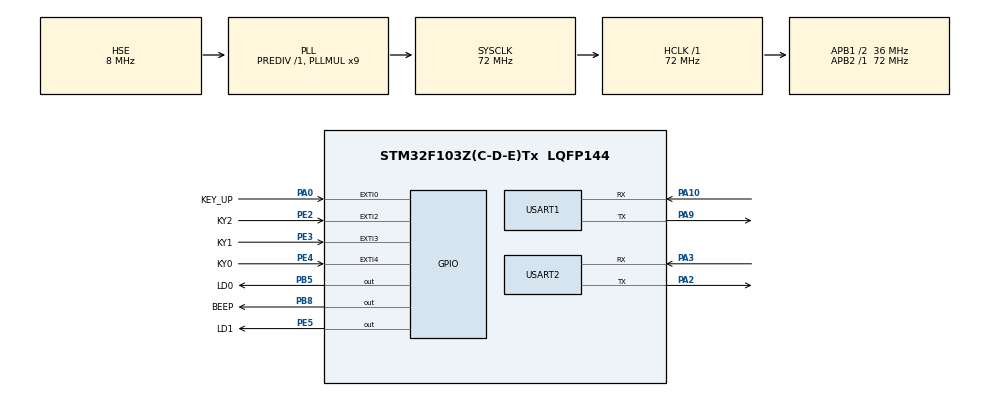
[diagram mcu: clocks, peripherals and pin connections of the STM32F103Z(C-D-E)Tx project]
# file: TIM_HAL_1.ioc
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Mcu.Family=STM32F1
Mcu.Name=STM32F103Z(C-D-E)Tx
Mcu.Package=LQFP144
NVIC.EXTI0_IRQn=true\:2\:0\:true\:false\:true\:true\:true
NVIC.EXTI2_IRQn=true\:3\:0\:true\:false\:true\:true\:true
NVIC.EXTI3_IRQn=true\:4\:0\:true\:false\:true\:true\:true
NVIC.EXTI4_IRQn=true\:5\:0\:true\:false\:true\:true\:true
NVIC.PriorityGroup=NVIC_PRIORITYGROUP_4
NVIC.TIM1_UP_IRQn=true\:0\:0\:false\:false\:true\:true\:true
NVIC.TIM4_IRQn=true\:0\:0\:false\:false\:true\:true\:true
NVIC.USART1_IRQn=true\:0\:0\:false\:false\:true\:true\:true
NVIC.USART2_IRQn=true\:0\:0\:false\:false\:true\:true\:true
OSC_IN.Mode=HSE-External-Oscillator
OSC_IN.Signal=RCC_OSC_IN
OSC_OUT.Mode=HSE-External-Oscillator
OSC_OUT.Signal=RCC_OSC_OUT
PA0-WKUP.GPIO_Label=KEY_UP
PA0-WKUP.GPIO_PuPd=GPIO_PULLDOWN
PA0-WKUP.Signal=GPXTI0
PA10.Mode=Asynchronous
PA10.Signal=USART1_RX
PA13.Mode=Serial_Wire
PA13.Signal=SYS_JTMS-SWDIO
PA14.Mode=Serial_Wire
PA14.Signal=SYS_JTCK-SWCLK
PA2.Mode=Asynchronous
PA2.Signal=USART2_TX
PA3.Mode=Asynchronous
PA3.Signal=USART2_RX
PA9.Mode=Asynchronous
PA9.Signal=USART1_TX
PB5.GPIO_Label=LD0
PB5.GPIO_PuPd=GPIO_PULLUP
PB5.Signal=GPIO_Output
PB8.GPIO_Label=BEEP
PB8.GPIO_PuPd=GPIO_PULLUP
PB8.Signal=GPIO_Output
PC14-OSC32_IN.Mode=LSE-External-Oscillator
PC14-OSC32_IN.Signal=RCC_OSC32_IN
PC15-OSC32_OUT.Mode=LSE-External-Oscillator
PC15-OSC32_OUT.Signal=RCC_OSC32_OUT
PE2.GPIO_Label=KY2
PE2.GPIO_ModeDefaultEXTI=GPIO_MODE_IT_FALLING
PE2.GPIO_PuPd=GPIO_PULLUP
PE2.Signal=GPXTI2
PE3.GPIO_Label=KY1
PE3.GPIO_ModeDefaultEXTI=GPIO_MODE_IT_FALLING
PE3.GPIO_PuPd=GPIO_PULLUP
PE3.Signal=GPXTI3
PE4.GPIO_Label=KY0
PE4.GPIO_ModeDefaultEXTI=GPIO_MODE_IT_FALLING
PE4.GPIO_PuPd=GPIO_PULLUP
PE4.Signal=GPXTI4
PE5.GPIO_Label=LD1
PE5.GPIO_PuPd=GPIO_PULLUP
PE5.Signal=GPIO_Output
ProjectManager.HeapSize=0x200
ProjectManager.StackSize=0x400
ProjectManager.TargetToolchain=MDK-ARM V5
RCC.AHBFreq_Value=72000000
RCC.APB1CLKDivider=RCC_HCLK_DIV2
RCC.APB1Freq_Value=36000000
RCC.APB1TimFreq_Value=72000000
RCC.APB2Freq_Value=72000000
RCC.APB2TimFreq_Value=72000000
RCC.HCLKFreq_Value=72000000
RCC.PLLMUL=RCC_PLL_MUL9
RCC.PLLSourceVirtual=RCC_PLLSOURCE_HSE
RCC.SYSCLKFreq_VALUE=72000000
RCC.SYSCLKSource=RCC_SYSCLKSOURCE_PLLCLK
RCC.USBFreq_Value=72000000
TIM1.AutoReloadPreload=TIM_AUTORELOAD_PRELOAD_ENABLE
TIM1.Period=1000
TIM1.Prescaler=35999
TIM4.AutoReloadPreload=TIM_AUTORELOAD_PRELOAD_ENABLE
TIM4.Period=4999
TIM4.Prescaler=7200-1
USART1.VirtualMode=VM_ASYNC
USART2.VirtualMode=VM_ASYNC
VP_TIM1_VS_ClockSourceINT.Mode=Internal
VP_TIM4_VS_ClockSourceINT.Mode=Internal
board=custom

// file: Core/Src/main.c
/* USER CODE BEGIN Header */
/**
  ******************************************************************************
  * @file           : main.c
  * @brief          : Main program body
  ******************************************************************************
  * @attention
  *
  * Copyright (c) 2022 STMicroelectronics.
  * All rights reserved.
  *
  * This software is licensed under terms that can be found in the LICENSE file
  * in the root directory of this software component.
  * If no LICENSE file comes with this software, it is provided AS-IS.
  *
  ******************************************************************************
  */
/* USER CODE END Header */
#include "main.h"
#include "tim.h"
#include "usart.h"
#include "gpio.h"

void SystemClock_Config(void);

/* USER CODE BEGIN 0 */
int i = 0;
/* USER CODE END 0 */

int main(void)
{

  /* MCU Configuration--------------------------------------------------------*/

  /* Reset of all peripherals, Initializes the Flash interface and the Systick. */
  HAL_Init();

  /* Configure the system clock */
  SystemClock_Config();

  /* Initialize all configured peripherals */
  MX_GPIO_Init();
  MX_USART2_UART_Init();
  MX_USART1_UART_Init();
  MX_TIM4_Init();
  MX_TIM1_Init();
  /* USER CODE BEGIN 2 */
  HAL_TIM_Base_Start_IT(&htim4);
  HAL_TIM_Base_Start_IT(&htim1);
  LOG("Init Successfully");
  /* USER CODE END 2 */

  /* Infinite loop */
  while (1)
  {

    /* USER CODE BEGIN 3 */
    i++;
    if (i % 20 == 0)
    {
      //LOG("LD0 Toggle");
      LD0_Toggle();
    }
    //HAL_Delay(500);
  }
  /* USER CODE END 3 */
}

void SystemClock_Config(void)
{
  RCC_OscInitTypeDef RCC_OscInitStruct = {0};
  RCC_ClkInitTypeDef RCC_ClkInitStruct = {0};

  /** Initializes the RCC Oscillators according to the specified parameters
  * in the RCC_OscInitTypeDef structure.
  */
  RCC_OscInitStruct.OscillatorType = RCC_OSCILLATORTYPE_HSE;
  RCC_OscInitStruct.HSEState = RCC_HSE_ON;
  RCC_OscInitStruct.HSEPredivValue = RCC_HSE_PREDIV_DIV1;
  RCC_OscInitStruct.HSIState = RCC_HSI_ON;
  RCC_OscInitStruct.PLL.PLLState = RCC_PLL_ON;
  RCC_OscInitStruct.PLL.PLLSource = RCC_PLLSOURCE_HSE;
  RCC_OscInitStruct.PLL.PLLMUL = RCC_PLL_MUL9;
  if (HAL_RCC_OscConfig(&RCC_OscInitStruct) != HAL_OK)
  {
    Error_Handler();
  }
  /** Initializes the CPU, AHB and APB buses clocks
  */
  RCC_ClkInitStruct.ClockType = RCC_CLOCKTYPE_HCLK|RCC_CLOCKTYPE_SYSCLK
                              |RCC_CLOCKTYPE_PCLK1|RCC_CLOCKTYPE_PCLK2;
  RCC_ClkInitStruct.SYSCLKSource = RCC_SYSCLKSOURCE_PLLCLK;
  RCC_ClkInitStruct.AHBCLKDivider = RCC_SYSCLK_DIV1;
  RCC_ClkInitStruct.APB1CLKDivider = RCC_HCLK_DIV2;
  RCC_ClkInitStruct.APB2CLKDivider = RCC_HCLK_DIV1;

  if (HAL_RCC_ClockConfig(&RCC_ClkInitStruct, FLASH_LATENCY_2) != HAL_OK)
  {
    Error_Handler();
  }
}

/* USER CODE BEGIN 4 */

void HAL_TIM_PeriodElapsedCallback(TIM_HandleTypeDef *htim)
{
  if (htim->Instance == htim1.Instance)
  {
    LOG("LD1 Toggle");
    LD1_Toggle();
  }
}
/* USER CODE END 4 */

void Error_Handler(void)
{
  __disable_irq();
  while (1)
  {
  }
}
